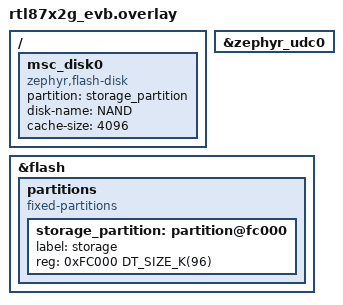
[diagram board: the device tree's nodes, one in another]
/*
 * Copyright(c) 2024, Realtek Semiconductor Corporation.
 *
 * SPDX-License-Identifier: Apache-2.0
 */

&zephyr_udc0 {
	status = "okay";
};


/delete-node/ &storage_partition;

&flash {
	partitions {
		compatible = "fixed-partitions";
		#address-cells = <1>;
		#size-cells = <1>;
		storage_partition: partition@fc000 {
			label = "storage";
			reg = <0xFC000 DT_SIZE_K(96)>;
		};
	};
};

/ {
	msc_disk0 {
		compatible = "zephyr,flash-disk";
		partition = <&storage_partition>;
		disk-name = "NAND";
		cache-size = <4096>;
	};
};
